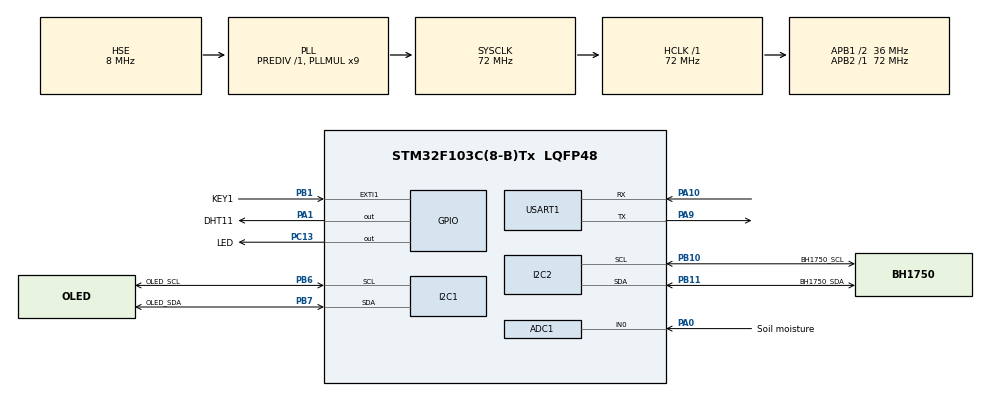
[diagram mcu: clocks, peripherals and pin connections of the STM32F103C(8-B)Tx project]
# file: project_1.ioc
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ADC1.Channel-2\#ChannelRegularConversion=ADC_CHANNEL_0
ADC1.NbrOfConversionFlag=1
ADC1.Rank-2\#ChannelRegularConversion=1
ADC1.SamplingTime-2\#ChannelRegularConversion=ADC_SAMPLETIME_55CYCLES_5
ADC1.master=1
I2C1.I2C_Mode=I2C_Fast
I2C2.I2C_Mode=I2C_Fast
Mcu.Family=STM32F1
Mcu.Name=STM32F103C(8-B)Tx
Mcu.Package=LQFP48
NVIC.EXTI1_IRQn=true\:0\:0\:false\:false\:true\:true\:true\:true
NVIC.PriorityGroup=NVIC_PRIORITYGROUP_4
PA0-WKUP.GPIO_Label=Soil moisture
PA0-WKUP.Signal=SharedAnalog_PA0
PA1.GPIO_Label=DHT11
PA1.GPIO_ModeDefaultOutputPP=GPIO_MODE_OUTPUT_OD
PA1.GPIO_PuPd=GPIO_NOPULL
PA1.GPIO_Speed=GPIO_SPEED_FREQ_HIGH
PA1.PinState=GPIO_PIN_SET
PA1.Signal=GPIO_Output
PA10.Mode=Asynchronous
PA10.Signal=USART1_RX
PA13.Mode=Serial_Wire
PA13.Signal=SYS_JTMS-SWDIO
PA14.Mode=Serial_Wire
PA14.Signal=SYS_JTCK-SWCLK
PA9.Mode=Asynchronous
PA9.Signal=USART1_TX
PB1.GPIO_Label=KEY1
PB1.GPIO_ModeDefaultEXTI=GPIO_MODE_IT_FALLING
PB1.GPIO_PuPd=GPIO_PULLUP
PB1.Signal=GPXTI1
PB10.GPIO_Label=BH1750_SCL
PB10.Mode=I2C
PB10.Signal=I2C2_SCL
PB11.GPIO_Label=BH1750_SDA
PB11.Mode=I2C
PB11.Signal=I2C2_SDA
PB6.GPIO_Label=OLED_SCL
PB6.Mode=I2C
PB6.Signal=I2C1_SCL
PB7.GPIO_Label=OLED_SDA
PB7.Mode=I2C
PB7.Signal=I2C1_SDA
PC13-TAMPER-RTC.GPIO_Label=LED
PC13-TAMPER-RTC.GPIO_ModeDefaultOutputPP=GPIO_MODE_OUTPUT_PP
PC13-TAMPER-RTC.PinState=GPIO_PIN_SET
PC13-TAMPER-RTC.Signal=GPIO_Output
PC14-OSC32_IN.Mode=LSE-External-Oscillator
PC14-OSC32_IN.Signal=RCC_OSC32_IN
PC15-OSC32_OUT.Mode=LSE-External-Oscillator
PC15-OSC32_OUT.Signal=RCC_OSC32_OUT
PD0-OSC_IN.Mode=HSE-External-Oscillator
PD0-OSC_IN.Signal=RCC_OSC_IN
PD1-OSC_OUT.Mode=HSE-External-Oscillator
PD1-OSC_OUT.Signal=RCC_OSC_OUT
ProjectManager.HeapSize=0x200
ProjectManager.StackSize=0x400
ProjectManager.TargetToolchain=MDK-ARM V5.32
RCC.AHBFreq_Value=72000000
RCC.APB1CLKDivider=RCC_HCLK_DIV2
RCC.APB1Freq_Value=36000000
RCC.APB1TimFreq_Value=72000000
RCC.APB2Freq_Value=72000000
RCC.APB2TimFreq_Value=72000000
RCC.HCLKFreq_Value=72000000
RCC.PLLMUL=RCC_PLL_MUL9
RCC.PLLSourceVirtual=RCC_PLLSOURCE_HSE
RCC.SYSCLKFreq_VALUE=72000000
RCC.SYSCLKSource=RCC_SYSCLKSOURCE_PLLCLK
RCC.USBFreq_Value=72000000
SH.SharedAnalog_PA0.0=GPIO_Analog
SH.SharedAnalog_PA0.1=ADC1_IN0,IN0
TIM1.Prescaler=71
USART1.VirtualMode=VM_ASYNC
VP_TIM1_VS_ClockSourceINT.Mode=Internal
board=custom

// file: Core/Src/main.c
/* USER CODE BEGIN Header */
/**
  ******************************************************************************
  * @file           : main.c
  * @brief          : Main program body
  ******************************************************************************
  * @attention
  *
  * Copyright (c) 2026 STMicroelectronics.
  * All rights reserved.
  *
  * This software is licensed under terms that can be found in the LICENSE file
  * in the root directory of this software component.
  * If no LICENSE file comes with this software, it is provided AS-IS.
  *
  ******************************************************************************
  */
/* USER CODE END Header */

#include "main.h"
#include "adc.h"
#include "i2c.h"
#include "tim.h"
#include "usart.h"
#include "gpio.h"

/* USER CODE BEGIN Includes */
#include "FreeRTOS.h"
#include "task.h"
#include "app_plant.h"
/* USER CODE END Includes */

void SystemClock_Config(void);

int main(void)
{

  /* MCU Configuration--------------------------------------------------------*/

  HAL_Init();

  SystemClock_Config();

  MX_GPIO_Init();
  MX_I2C1_Init();
  MX_USART1_UART_Init();
  MX_ADC1_Init();
  MX_TIM1_Init();
  MX_I2C2_Init();

  /* USER CODE BEGIN 2 */

  if (AppPlant_Start() == 0U)
  {
    Error_Handler();
  }

  vTaskStartScheduler();

  /* USER CODE END 2 */

  while (1)
  {

    /* USER CODE BEGIN 3 */
    Error_Handler();
  }
  /* USER CODE END 3 */
}

void SystemClock_Config(void)
{
  RCC_OscInitTypeDef RCC_OscInitStruct = {0};
  RCC_ClkInitTypeDef RCC_ClkInitStruct = {0};
  RCC_PeriphCLKInitTypeDef PeriphClkInit = {0};

  RCC_OscInitStruct.OscillatorType = RCC_OSCILLATORTYPE_HSE;
  RCC_OscInitStruct.HSEState = RCC_HSE_ON;
  RCC_OscInitStruct.HSEPredivValue = RCC_HSE_PREDIV_DIV1;
  RCC_OscInitStruct.HSIState = RCC_HSI_ON;
  RCC_OscInitStruct.PLL.PLLState = RCC_PLL_ON;
  RCC_OscInitStruct.PLL.PLLSource = RCC_PLLSOURCE_HSE;
  RCC_OscInitStruct.PLL.PLLMUL = RCC_PLL_MUL9;
  if (HAL_RCC_OscConfig(&RCC_OscInitStruct) != HAL_OK)
  {
    Error_Handler();
  }

  RCC_ClkInitStruct.ClockType = RCC_CLOCKTYPE_HCLK | RCC_CLOCKTYPE_SYSCLK |
                                RCC_CLOCKTYPE_PCLK1 | RCC_CLOCKTYPE_PCLK2;
  RCC_ClkInitStruct.SYSCLKSource = RCC_SYSCLKSOURCE_PLLCLK;
  RCC_ClkInitStruct.AHBCLKDivider = RCC_SYSCLK_DIV1;
  RCC_ClkInitStruct.APB1CLKDivider = RCC_HCLK_DIV2;
  RCC_ClkInitStruct.APB2CLKDivider = RCC_HCLK_DIV1;

  if (HAL_RCC_ClockConfig(&RCC_ClkInitStruct, FLASH_LATENCY_2) != HAL_OK)
  {
    Error_Handler();
  }

  PeriphClkInit.PeriphClockSelection = RCC_PERIPHCLK_ADC;
  PeriphClkInit.AdcClockSelection = RCC_ADCPCLK2_DIV2;
  if (HAL_RCCEx_PeriphCLKConfig(&PeriphClkInit) != HAL_OK)
  {
    Error_Handler();
  }
}

void Error_Handler(void)
{
  __disable_irq();
  while (1)
  {
  }
}

#ifdef USE_FULL_ASSERT
void assert_failed(uint8_t *file, uint32_t line)
{
  /* USER CODE BEGIN 6 */
  (void)file;
  (void)line;
  /* USER CODE END 6 */
}
#endif /* USE_FULL_ASSERT */
